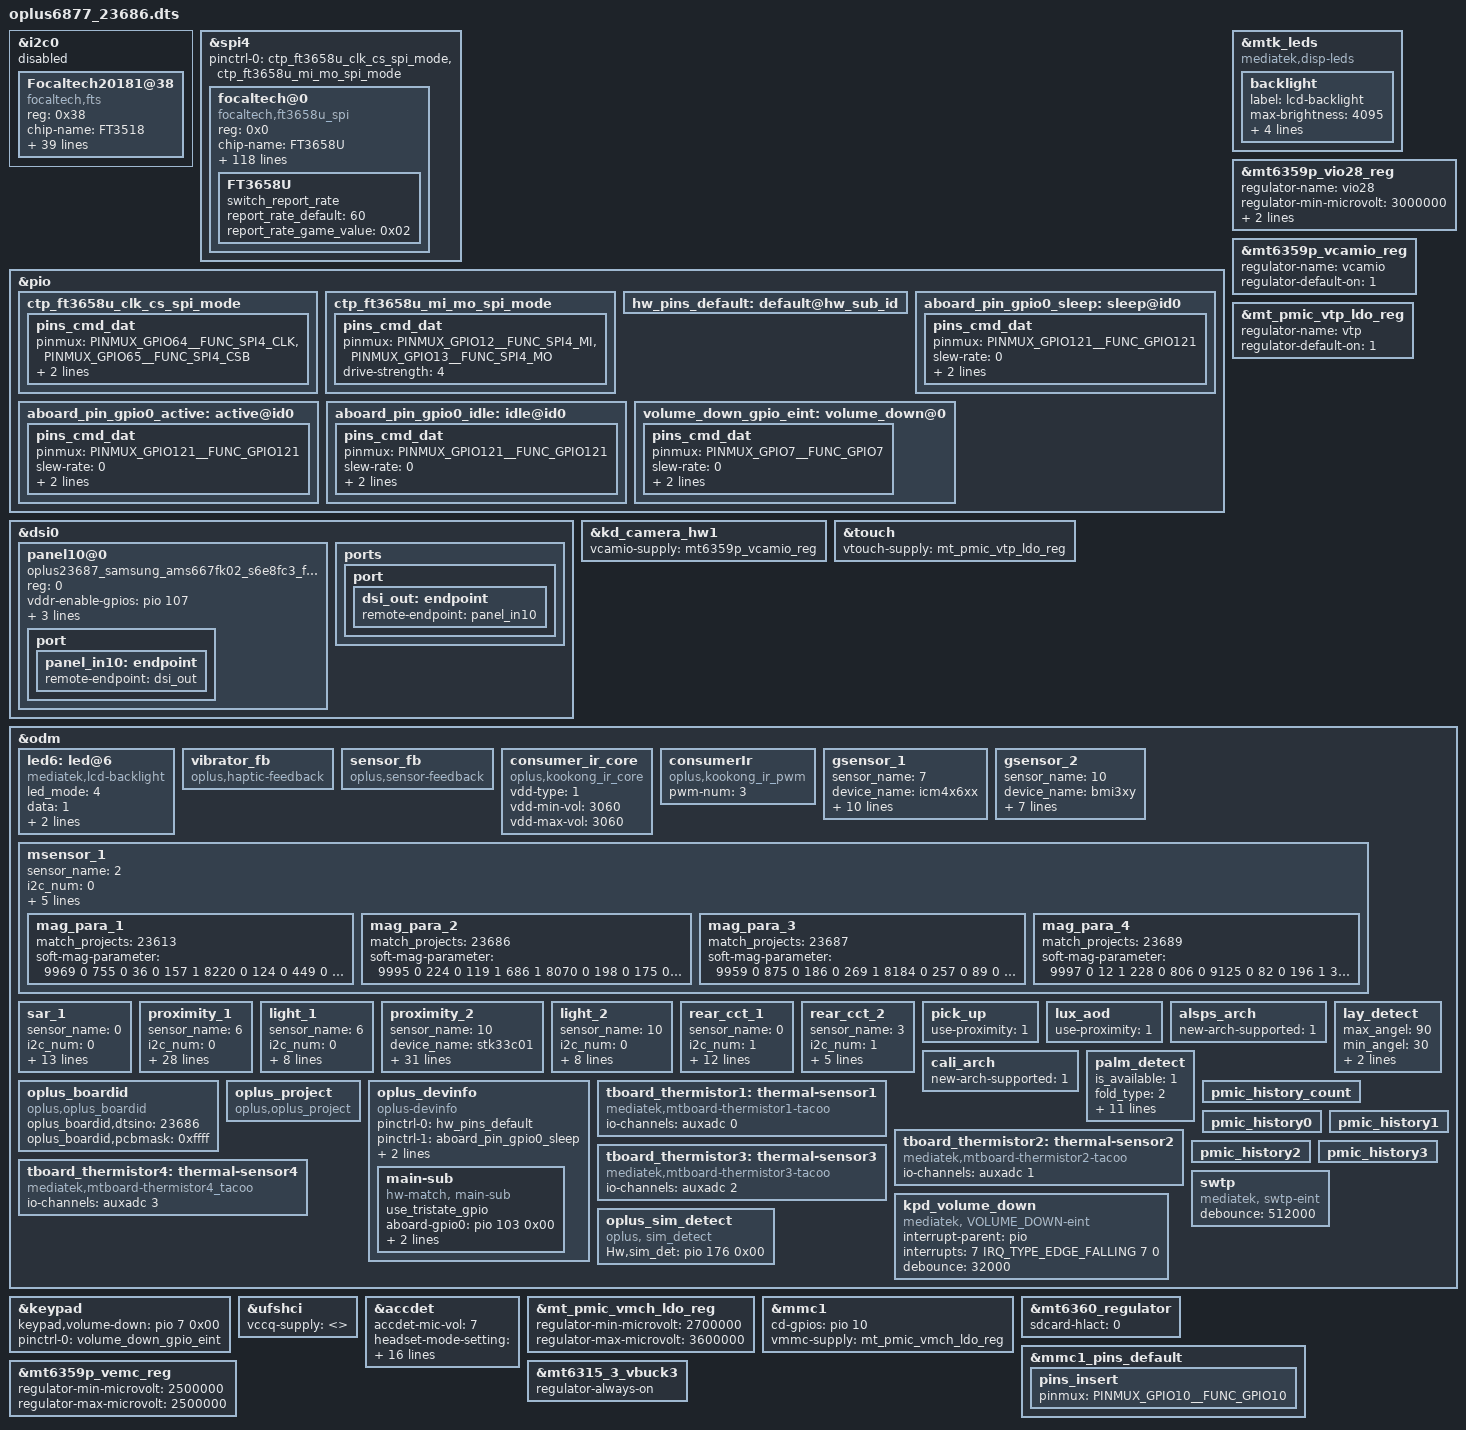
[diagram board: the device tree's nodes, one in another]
// SPDX-License-Identifier: (GPL-2.0 OR MIT)
/*
 * Copyright (C) 2022 MediaTek Inc.
 */
#include "k6877v1_64.dts"

/* #ifdef CONFIG_UFF_FINGERPRINT */
#include "mediatek/oplus_uff_23613_23686_23687.dtsi"
/* #endif CONFIG_UFF_FINGERPRINT */

/*touch start*/

&i2c0 {
	status = "disable";
		Focaltech20181@38 {
		compatible = "focaltech,fts";
		reg = <0x38>;
		chip-name = "FT3518";

		/* Interrupt && Irq-gpio */
		interrupt-parent = <&pio>;
		interrupts = <14 0x2002>;

		/* Power Config */
		vdd_2v8-supply  = <&mt_pmic_vtp_ldo_reg>;
		vdd_2v8_volt = <3000000>;

		/* Other HW Resource */
		irq-gpio = <&pio 14 0x2002>;
		reset-gpio = <&pio 15 0x1>;
		//pinctrl-names = "default";
		//pinctrl-0 = <&ctp_ts_int_active &ctp_ts_reset_active>;

		vid_len = <2>;
		tp_type = <8>;
		// type of tp_dev ,TP-SAMSUNG = 8;
		platform_support_project = <23231>;
		platform_support_project_dir = <23231>;
		platform_support_project_commandline = "default_commandline", "default_commandline", "default_commandline";

		touchpanel,max-num-support = <10>;
		touchpanel,tx-rx-num = <16 34>;
		touchpanel,panel-coords = <4320 9600>;
		touchpanel,display-coords = <1080 2400>;
		touchpanel,touchmajor-limit = <0 216>;
		touchpanel,report-rate = <120 180>;
		touchpanel,smooth-level = <255 2 15 25 45 60>;
		touchpanel,smooth-level-charging = <255 15 20 25 45 60>;
		touchpanel,sensitive-level = <255 20 16 13 10 5>;
		touchpanel,single-optimized-time = <8>;

		//prevention,dead_area_width = <20 20>;
		//prevention,condition_area_width = <60 60 160 160>;
		//prevention,eli_area_width = <240 1000 1200 240>;

		/* SW Support Feature Control */
		black_gesture_support;
		//black_gesture_indep_support;
		fw_edge_limit_support;
		pressure_report_support;
		charger_pump_support;
		game_switch_support;
		smart_gesture_support;
		fw_update_app_support;
		fingerprint_underscreen_support;
		headset_pump_support;
		//irq_need_dev_resume_ok;
		health_monitor_v2_support;
		high_resolution_support;
		//esd_handle_support;
		lcd_tp_refresh_support;
		exception_upload_support;
		/*
		 *Virtual Key Config:
		 *1:touchpanel,button-type: <virtualkey_type  supportted_button-map>
		 *virtualkey_type:
		 *Type 1: using board_properties
		 *Type 2: using same IC (button zone&& touch zone are seprate)
		 *Type 3: using diffrent IC (button zone&& touch zone are seprate)
		 *Type 4: No need of virtual key process
		 *supportted_button-map:select|menu|home|back
		 *
		 *2:touchpanel,button-map
		 *type (X1,Y1)(X2,Y2)(X3,Y3)(Width_X,Hight_Y)--Only when button-type is 0
		 */
		touchpanel,button-type = <4>;
		touchpanel.button-TRx = <0 0>;
	};
};

&spi4 {
	status = "okay";
	#address-cells = <1>;
	#size-cells = <0>;

	pinctrl-names = "default";
	pinctrl-0 = <&ctp_ft3658u_clk_cs_spi_mode>, <&ctp_ft3658u_mi_mo_spi_mode>;

	focaltech@0{
		compatible = "focaltech,ft3658u_spi";
		reg = <0x0>;
		chip-name = "FT3658U";
		status = "okay";
		spi-max-frequency = <6000000>;
		/* Interrupt && Irq-gpio */
		interrupt-parent = <&pio>;
		interrupts = <14 0x2002>;
		panel_type = <8>; /* panel-SAMSUNG*/
		/* Power Config */
		project_id = <23687>;
		vdd_2v8-supply  = <&mt_pmic_vtp_ldo_reg>;
		vdd_2v8_volt = <3000000>;



		/* Other HW Resource */

		irq-gpio = <&pio 14 0x2002>;
		reset-gpio = <&pio 15 0x1>;

		touchpanel,max-num-support = <10>;
		touchpanel,tx-rx-num = <16 34>;
		earsense,tx-rx-num = <17 18>;
		touchpanel,panel-coords = <8640 19200>;
		touchpanel,display-coords = <1080 2400>;
		touchpanel,touchmajor-limit = <128 216>;
		touchpanel,elimination-range = <20 200 200>;
		//touchpanel,int-mode = <1>; /*0: interrupt and disable, 1:interrupt and not disable*/
		touchpanel,msecs-to-jiffies-time = <150>;
		touchpanel,smooth-level = <0 110 115 120 140 155>;
		touchpanel,smooth-level-charging = <0 110 115 120 140 155>;
		touchpanel,sensitive-level = <0 19 16 14 13 10>;
		touchpanel,tp-index = <0>;
		touchpanel,high-frame-rate-time = <20>;

		vid_len = <2>;
		firmware_name = "0xAB30500";
		tp_type = <8>; /* panel-SAMSUNG*/
		platform_support_project = <23613 23686 23687 23689 23707 23709>;
		platform_support_project_dir = <23687 23687 23687 23687 23687 23687>;
		platform_support_project_commandline = "default_commandline","default_commandline","default_commandline","default_commandline","default_commandline","default_commandline";

        prevention,curved_screen_V2;
        prevention,grip_disable_level = <6>;
        prevention,updelay_time_ms = <30>;
        prevention,makeup_cnt_weight = <4 1 2 2 2>;
        prevention,large_corner_range = <960 2400>;
        prevention,large_corner_judge_condition = <500 300 800 7 7>;
        prevention,trx_reject_condition = <9 6 7>;
        prevention,trx_strict_reject_condition = <8 5 6>;
        prevention,large_judge_time_ms = <500 50 30>;
        prevention,large_exit_condition = <8 8 2>;
        prevention,single_channel_width = <160 160>;
        prevention,normal_tap_condition = <10 350>;
        prevention,long_edge_condition = <200 80 180 80>;
        prevention,long_strict_edge_condition = <160 60>;
        prevention,long_fingerhold_condition = <50 6 4 4>;
        prevention,short_edge_condition = <200 80 180 80>;
        prevention,short_strict_edge_condition = <160 60>;
        prevention,large_strict_exit_condition = <4 4>;
        prevention,top_corner_config = <440 1200 360>;
        prevention,edge_swipe_config = <240 960>;

        prevention,curved_screen_V4;
        prevention,long_eliminate_point_type = <2 8640 6400 240 19200 300 1>;
        prevention,long_fingerhold_condition2 = <420 0 0 0>;
        prevention,top_corner_config2 = <3 80 480 0 0>;
        prevention,hor_long_top_corner_config = <240 1600 0 0>;
        prevention,top_middle_config = <8640 800 800 0>;
        prevention,corner_eliminate_point_type = <0 960 1600 1>;
        prevention,finger_hold_differ_size = <1 0 240 300>;
        prevention,finger_hold_max_rx_exit_distance = <5 240 1600>;
        prevention,max_rx_exit_distance = <1 5 150 240 1600>;
        prevention,dynamic_finger_hold_exit_distance = <1 240 1600 360>;
        prevention,edge_sliding_matched_support = <1 150 3 0>;

        //grip v4.2 reclining mode
        prevention,reclining_mode_support = <1>;
        prevention,long_eliminate_point_type_recli = <2 8640 6400 240 19200 500 0>;
        prevention,finger_hold_differ_size_recli = <1 0 240 400>;
        prevention,finger_hold_max_rx_exit_distance_recli = <4 240 1600>;
        prevention,max_rx_exit_distance_recli = <1 4 100 240 1600>;
        prevention,dynamic_finger_hold_exit_distance_recli = <1 240 1600 360>;
        prevention,edge_sliding_matched_support_recli = <1 200 3 0>;
        prevention,long_edge_condition_recli = <160 80 120 80>;

		/* SW Support Feature Control */
		//esd_handle_support;
		//register-is-16bit;
		//wireless_charger_support;
		headset_pump_support;
		//fw_edge_limit_support;

		health_monitor_support;
		black_gesture_support;
		charger_pump_support;
		//lcd_tp_refresh_support;
		fw_update_app_support;
		smart_gesture_support;
		game_switch_support;
		report_flow_unlock_support;
		kernel_grip_support;
		fingerprint_underscreen_support;
		pressure_report_support;
		touchpanel,single-optimized-time = <8>;
		auto_test_force_pass_support;
		snr_read_support;
		high_resolution_support_x8;
		algorithm_support;
		screenoff_fingerprint_info_support;
		irq_need_dev_resume_ok;
		sportify_aod_gesture_support;
		black_gesture_indep_support;
		thermal_detect_support;
		exception_upload_support;
		palm_to_sleep_support;
		diaphragm_touch_support;
		force_water_mode_support;

		/*
		 *Virtual Key Config:
		 *1:touchpanel,button-type: <virtualkey_type  supportted_button-map>
		 *virtualkey_type:
		 *Type 1: using board_properties
		 *Type 2: using same IC (button zone&& touch zone are seprate)
		 *Type 3: using diffrent IC (button zone&& touch zone are seprate)
		 *Type 4: No need of virtual key process
		 *supportted_button-map:select|menu|home|back
		 *
		 *2:touchpanel,button-map
		 *type (X1,Y1)(X2,Y2)(X3,Y3)(Width_X,Hight_Y)--Only when button-type is 0
		 */
		touchpanel,button-type = <4>;
		touchpanel.button-TRx = <0 0>;

		FT3658U {
			switch_report_rate;
			report_rate_default = <60>;
			report_rate_game_value = <0x02>;
		};
	};
};

&pio {
	ctp_ft3658u_clk_cs_spi_mode: ctp_ft3658u_clk_cs_spi_mode{
		pins_cmd_dat {
			pinmux = <PINMUX_GPIO64__FUNC_SPI4_CLK>,
				<PINMUX_GPIO65__FUNC_SPI4_CSB>;
			mediatek,drive-strength-adv = <0>;/*EH[2:0]*/
			drive-strength = <4>;
		};
	};
	ctp_ft3658u_mi_mo_spi_mode: ctp_ft3658u_mi_mo_spi_mode {
		pins_cmd_dat {
			pinmux = <PINMUX_GPIO12__FUNC_SPI4_MI>,
				<PINMUX_GPIO13__FUNC_SPI4_MO>;
			drive-strength = <4>;
		};
	};

};
/*touch end*/



&dsi0 {
	status = "okay";
	#address-cells = <1>;
	#size-cells = <0>;
	panel10@0 {
		compatible = "oplus23687_samsung_ams667fk02_s6e8fc3_fhdp_dsi_vdo";
		reg = <0>;
		vddr-enable-gpios = <&pio 107 0>;
		vci-enable-gpios = <&pio 105 0>;
		reset-gpios = <&pio 40 0>;
                oplus,ofp-fp-type = <0x200>;
		pinctrl-names = "default";
		port {
			panel_in10: endpoint {
				remote-endpoint = <&dsi_out>;
			};
		};
	};
	ports {
		port {
			dsi_out: endpoint {
				remote-endpoint = <&panel_in10>;
			};
		};
	};
};

&mtk_leds {
	compatible = "mediatek,disp-leds";
	backlight {
		label = "lcd-backlight";
		max-brightness = <4095>;
		max-hw-brightness = <4095>;
		led-bits = <12>;
		trans-bits = <12>;
		default-state = "on";
	};
};

&mt6359p_vio28_reg {
	regulator-name = "vio28";
	regulator-min-microvolt = <3000000>;
	regulator-max-microvolt = <3000000>;
	regulator-enable-ramp-delay = <0>;
};

&mt6359p_vcamio_reg {
	regulator-name = "vcamio";
	regulator-default-on = <1>; /* 0:skip, 1: off, 2:on */
	status = "okay";
};
&mt_pmic_vtp_ldo_reg {
	regulator-name = "vtp";
	regulator-default-on = <1>; /* 0:skip, 1: off, 2:on */
	status = "okay";
};

&kd_camera_hw1 {
	vcamio-supply = <&mt6359p_vcamio_reg>;
	status = "okay";
};

&touch {
	vtouch-supply = <&mt_pmic_vtp_ldo_reg>;
	status = "okay";
};

&odm {
/*
	/delete-node/ led@6;
*/

	led6:led@6 {
		compatible = "mediatek,lcd-backlight";
		led_mode = <4>;
		data = <1>;
		led_config = <8 11>;
		pwm_config = <0 1 0 0 0>;
	};

	vibrator_fb:vibrator_fb {
		compatible = "oplus,haptic-feedback";
	};
/* sensor start */
	sensor_fb: sensor_fb {
		compatible = "oplus,sensor-feedback";
	};
	consumer_ir_core: consumer_ir_core {
		compatible = "oplus,kookong_ir_core";
		status = "okay";
		vdd-type = <1>;
		vdd-min-vol = <3060>;
		vdd-max-vol = <3060>;
	};
	consumerIr: consumerIr {
		compatible = "oplus,kookong_ir_pwm";
		status = "okay";
		pwm-num = <3>;
	};
	/*
	enum {
		LIS3DH,
		LSM6DS3,
		BMI160,
		LIS2HH12,
		LSM6DSM,
		BMI2XY,
		LSM6DSO,
		BMA4XY,
		SC7A20,
		ICM4X6XX,
	};
	*/
	gsensor_1: gsensor_1 {
		status = "okay";
		sensor_name = <7>;//ICM4X6XX
		device_name = "icm4x6xx";
		i2c_num = <2>;
		i2c_addr = <0>;
		direction = <2>;
		eint_num = <1>;
		step_count_7_en = <1>;
		config_miso = <1>;
		correct_y_bias = <1>;
		gyro_cali_version= <2>;
		gyro_cali_range = <350>; //0.35 rad/s
		acc_cali_range= <300 300 300>; //250mg
	};
	gsensor_2: gsensor_2 {
		status = "okay";
		sensor_name = <10>;//BMI3XY
		device_name = "bmi3xy";
		i2c_num = <2>;
		i2c_addr = <0>;
		direction = <1>;
		eint_num = <1>;
		gyro_cali_version= <2>;
		gyro_cali_range = <350>; //0.35 rad/s
		acc_cali_range= <300 300 300>; //250mg
	};
	/*
	enum {
		AKM09911,
		MMC3530,
		MMC5603,
		MXG4300,
	};
	*/
	msensor_1: msensor_1 {
		status = "okay";
		sensor_name = <2>;//MMC5603
		i2c_num = <0>;
		i2c_addr = <48>;
		direction = <3>;
		eint_num = <0>;
		para_num = <4>;
		libname = "mmc";
		mag_para_1 {
			match_projects = <23613>;
			soft-mag-parameter = <9969 0 755 0 36 0 157 1 8220 0 124 0 449 0 24 0 10391 0>;
		};
		mag_para_2 {
			match_projects = <23686>;
			soft-mag-parameter = <9995 0 224 0 119 1 686 1 8070 0 198 0 175 0 387 0 10181 0>;
		};
		mag_para_3 {
			match_projects = <23687>;
			soft-mag-parameter = <9959 0 875 0 186 0 269 1 8184 0 257 0 89 0 120 0 10452 0>;
		};
		mag_para_4 {
			match_projects = <23689>;
			soft-mag-parameter = <9997 0 12 1 228 0 806 0 9125 0 82 0 196 1 333 0 10375 0>;
		};
	};
	sar_1: sar_1 {
		status = "okay";
		sensor_name = <0>;//SX933x
		i2c_num = <0>;
		i2c_addr = <40>;
		direction = <4>;
		eint_num = <13>;
		channel_num = <2>;
		channel_0_min = <0>;
		channel_0_max = <70000>;
		channel_1_min = <0>;
		channel_1_max = <70000>;
		channel_2_min = <0>;
		channel_2_max = <70000>;
		channel_3_min = <0>;
		channel_3_max = <70000>;
		reg_table_num = <3>;
	};
	/*
	enum {
		TMD2725,
		APSD9922,
		STK3335,
		STK3331,
		STK2232,
		TCS3701,
		STK32600,
	};
	*/
	proximity_1: proximity_1 {
		status = "okay";
		sensor_name = <6>;//STK32600
		i2c_num = <0>;
		i2c_addr = <72>;
		direction = <4>;
		eint_num = <2>;
		low_step = <300>;
		high_step = <400>;
		low_limit = <400>;
		high_limit = <600>;
		dirty_low_step = <300>;
		dirty_high_step = <400>;
		ps_dirty_limit = <1800>;
		ps_ir_limit = <2000>;
		ps_adjust_min = <0>;
		ps_adjust_max = <1850>;
		sampling_count = <5>;
		step_max = <400>;
		step_min = <100>;
		step_div = <2000>;
		anti_shake_delta = <70>;
		dynamic_cali_max = <5000>;
		raw2offset_radio = <1000>;
		offset_max = <60000>;
		offset_range_min = <0>;
		offset_range_max = <65535>;
		force_cali_limit = <2000>;
		cali_jitter_limit = <30>;
		cal_offset_margin = <3000>;
		sensor-reg = <0x03 0x28>;
		is_use_force_cali = <1>;
	};
	light_1: light_1 {
		status = "okay";
		sensor_name = <6>;//STK32600
		i2c_num = <0>;
		i2c_addr = <72>;
		direction = <4>;
		eint_num = <2>;
		als_buffer_length =<8>;
		als_ratio = <110>;
		als_type = <2>;//<1-normal;2-under screen;3-normal needed compensation>
		device_name = "stk32600";
		use_als_c2 = <1>;
	};
	proximity_2: proximity_2 {
		status = "okay";
		sensor_name = <10>;//STK33C01
		device_name = "stk33c01";
		i2c_num = <0>;
		i2c_addr = <72>;
		direction = <4>;
		eint_num = <2>;
		low_step = <300>;
		high_step = <400>;
		low_limit = <400>;
		high_limit = <600>;
		dirty_low_step = <300>;
		dirty_high_step = <400>;
		ps_dirty_limit = <1800>;
		ps_ir_limit = <2000>;
		ps_adjust_min = <0>;
		ps_adjust_max = <1850>;
		sampling_count = <5>;
		step_max = <400>;
		step_min = <100>;
		step_div = <2000>;
		anti_shake_delta = <70>;
		dynamic_cali_max = <5000>;
		raw2offset_radio = <1000>;
		offset_max = <60000>;
		offset_range_min = <0>;
		offset_range_max = <65534>;
		force_cali_limit = <2000>;
		cali_jitter_limit = <30>;
		cal_offset_margin = <3000>;
		is_use_force_cali = <1>;
		parameter-number = <8>;
		sensor-reg = <0x01 0x44
				0x03 0x28
				0x05 0x3F
				0xDB 0x00>; //override special reg
	};
	light_2: light_2 {
		status = "okay";
		sensor_name = <10>;//STK33C01
		i2c_num = <0>;
		i2c_addr = <72>;
		direction = <4>;
		eint_num = <2>;
		als_buffer_length =<8>;
		als_ratio = <110>;
		als_coef_ratio = <88>;
		als_type = <2>;//<1-normal;2-under screen;3-normal needed compensation>
		device_name = "stk33c01";

	};
	/*
	enum {
		STK37600,
		MN29005,
		TCS3408,
	};
	*/
	rear_cct_1: rear_cct_1 {
		status = "okay";
		sensor_name = <0>;//STK37600
		i2c_num = <1>;
		i2c_addr = <0x48>;
		direction = <0>;
		eint_num = <10>;
		available_sensor = <7>; // bit 0: rear als, bit 1: rear cct, bit 2: rear flicker
		gold_rear_cct_3k = <11083 14060 1700 488 64 42136>; // 3000k gold parameter
		gold_rear_cct_6k = <8488 13068 3928 372 64 42964>;  // 3000k gold parameter
		device_name = "stk37600";
		cct_coef_Lir = <9116000 0 259000 0 1711000 1 7351000 0 12875000 0
				1686000 0 3545000 0 6606000 0 51505000 0 3221000 1
				2492000 1 2826000 1>;
		cct_coef_Hir = <178000 1 14775000 1 36798000 1 13552000 0 24758000 0
				31340000 0 3274000 1 7368000 1 19817000 0 161000 1
				23000 0 392000 0>;
	};
	rear_cct_2: rear_cct_2 {
		status = "okay";
		sensor_name = <3>;//SIP1221LR1N
		i2c_num = <1>;
		i2c_addr = <0x59>;
		direction = <0>;
		eint_num = <10>;
		available_sensor = <4>; // bit 0: rear als, bit 1: rear cct, bit 2: rear flicker
		device_name = "sip1221lr1n";
	};
	pick_up: pick_up {
		status = "okay";
		use-proximity = <1>;
	};
	lux_aod: lux_aod {
		status = "okay";
		use-proximity = <1>;
	};
	alsps_arch: alsps_arch {
		status = "okay";
		new-arch-supported = <1>;
	};
	cali_arch: cali_arch {
		status = "okay";
		new-arch-supported = <1>;
	};
	lay_detect: lay_detect{
		status = "okay";
		max_angel = <90>;
		min_angel = <30>;
		lay_in_time = <10>;
		lay_out_time = <3>;
	};
	palm_detect: palm_detect{
		status = "okay";
		is_available = <1>;
		fold_type = <2>;
		prox_type = <0>;
		x_limit = <1>;
		y_limit = <6>;
		z_limit = <6>;
		delta_ms_limit = <5000>;
		delta_ms_low = <200>;
		x_gyro_limit = <300000>;
		y_gyro_limit = <300000>;
		z_gyro_limit = <300000>;
		move_limit = <8>;
		als_limit = <3>;
	};
/* sensor end */

	oplus_boardid:oplus_boardid {
		compatible = "oplus,oplus_boardid";
		oplus_boardid,dtsino="23686";//only one u32
		oplus_boardid,pcbmask="0xffff";//all mask 0xffff
	};

/* OPLUS_BUG_STABILITY oplus project start */
	oplus_project:oplus_project {
		compatible = "oplus,oplus_project";
	};
	oplus_devinfo:oplus_devinfo {
		compatible = "oplus-devinfo";

		pinctrl-names = "default", "aboard_gpio0_sleep", "aboard_gpio0_active", "aboard_gpio0_idle";
		pinctrl-0 = <&hw_pins_default>;
		pinctrl-1 = <&aboard_pin_gpio0_sleep>;
		pinctrl-2 = <&aboard_pin_gpio0_active>;
		pinctrl-3 = <&aboard_pin_gpio0_idle>;
		main-sub {
			use_tristate_gpio;
			compatible = "hw-match, main-sub";
			aboard-gpio0 = <&pio 103 0x00>;
			aboard-patterns = <2 1 0>;
			/*main board*/
			match-projects = <23613 23686 23687>;
		};
	};

/* OPLUS_BUG_STABILITY oplus project end */

/* 20221216, add for AP, 4G pA, 5G PA, charger, sub_bat, flashlight ntc*/
 	tboard_thermistor1: thermal-sensor1 {
 		compatible = "mediatek,mtboard-thermistor1-tacoo";
 		io-channels = <&auxadc 0>;
 		io-channel-names = "thermistor-ch0";
 	};
 	tboard_thermistor2: thermal-sensor2 {
 		compatible = "mediatek,mtboard-thermistor2-tacoo";
 		io-channels = <&auxadc 1>;
 		io-channel-names = "thermistor-ch1";
 	};
 	tboard_thermistor3: thermal-sensor3 {
 		compatible = "mediatek,mtboard-thermistor3-tacoo";
 		io-channels = <&auxadc 2>;
 		io-channel-names = "thermistor-ch2";
 	};
	tboard_thermistor4: thermal-sensor4 {
 		compatible = "mediatek,mtboard-thermistor4_tacoo";
 		io-channels = <&auxadc 3>;
 		io-channel-names = "thermistor-ch3";
	};
	kpd_volume_down:kpd_volume_down {
		compatible = "mediatek, VOLUME_DOWN-eint";
		interrupt-parent = <&pio>;
		interrupts = <7 IRQ_TYPE_EDGE_FALLING 7 0>;/*TRQ num 29 is linked with gpio29 (mt6877)*/
		debounce = <32000>;
		status = "okay";
	};

	pmic_history_count:pmic_history_count {
	};
	pmic_history0:pmic_history0 {
	};
	pmic_history1:pmic_history1 {
	};
	pmic_history2:pmic_history2 {
	};
	pmic_history3:pmic_history3 {
	};
	//#ifdef OPLUS_VENDOR_SWTP
	swtp: swtp {
		compatible = "mediatek, swtp-eint";
		debounce = <512000>;
	};
	//#endif  /*OPLUS_VENDOR_SWTP*/

};

&odm {
/* Add for sim detect */
    oplus_sim_detect {
        compatible = "oplus, sim_detect";
        Hw,sim_det = <&pio 176 0x00>;
    };
};

&pio {
        hw_pins_default:default@hw_sub_id {
        };

        aboard_pin_gpio0_sleep:sleep@id0 {
                pins_cmd_dat {
                        pinmux = <PINMUX_GPIO121__FUNC_GPIO121>;
                        slew-rate = <0>;
                        bias-pull-down;
                        input-enable;
                };
        };

        aboard_pin_gpio0_active:active@id0 {
                pins_cmd_dat {
                        pinmux = <PINMUX_GPIO121__FUNC_GPIO121>;
                        slew-rate = <0>;
                        bias-pull-up;
                        input-enable;
                };
        };

        aboard_pin_gpio0_idle:idle@id0 {
                pins_cmd_dat {
                        pinmux = <PINMUX_GPIO121__FUNC_GPIO121>;
                        slew-rate = <0>;
                        bias-disable;
                        input-enable;
                };
        };
};

&keypad {
        keypad,volume-down = <&pio 7 0x00>;
        pinctrl-names = "volume_down_as_int";
        pinctrl-0 = <&volume_down_gpio_eint>;
        status = "okay";
};

&pio {
        volume_down_gpio_eint:volume_down@0{
                pins_cmd_dat {
                        pinmux = <PINMUX_GPIO7__FUNC_GPIO7>;
                        slew-rate = <0>;  /*direction 0:in, 1:out*/
                        input-enable;
			bias-disable;
                };
        };
};

&ufshci {
    vccq-supply = <>;
};

&accdet {
	/* accdet micbias voltage: 0x09:2.85v 0x08:2.8v 0x07,
	 * 2.7v;0x05,2.5v;0x02,1.9v
	 */
	accdet-mic-vol = <7>;
	/* accdet pwm_width, pwm_thresh, fall_delay, rise_delay
	 * debounce0, debounce1, debounce3, debounce4
	 * eint pwm_width, eint pwm_thresh
	 * eint deb(debounce0, debounce1, debounce2, debounce3), inv_debounce
	 */
	//#ifdef OPLUS_ARCH_EXTENDS
	/* Modify for bug 136344 */
	headset-mode-setting = <0x500 0x500 1 0x1f0
				0x1325 0x800 0x3D4 0x44
				0x0 0x7
				0x5 0x9 0x9 0xd 0xe>;
	//#else /* OPLUS_ARCH_EXTENDS */
	/*headset-mode-setting = <0x500 0x500 1 0x1f0
	*                      0x800 0x800 0x20 0x44
	*                      0x4 0x1
	*                      0x5 0x3 0x3 0x5 0xe>;
	*/
	//#endif /* OPLUS_ARCH_EXTENDS */
	accdet-plugout-debounce = <1>;
	/*1:ACC mode, 2:low cost without in bias, 6:low cost with in bias*/
	accdet-mic-mode = <2>;
	/*0--MD_MAX--UP_MAX--DW_MAX*/
	headset-three-key-threshold = <0 82 170 306>;
	//#else
	//headset-three-key-threshold = <0 80 220 400>;
	//#endif
	headset-three-key-threshold-CDD = <0 121 192 600>;
	/*0--MD_MAX--VOICE_MAX--UP_MAX--DW_MAX*/
	headset-four-key-threshold = <0 58 121 192 400>;

//#ifdef OPLUS_ARCH_EXTENDS
	/* moisture HW mode config start. Enable moisture detection or not
	 * default use HW mode for moisture detection
	 */
	moisture_detect_enable = <1>;
//#endif /* OPLUS_ARCH_EXTENDS */
	/* select VTH to 2v and 500k, use internal resitance */
	eint_use_ext_res = <0>;
//#ifdef OPLUS_ARCH_EXTENDS
	/* enable eint detection mode, if moisture detection enable
	 * eint_detect_mode = moisture_detect_mode;otherwise, select
	 * eint_detect_mode = 4 as DEFAULT
	 */
	eint_detect_mode = <5>;
	/* enable moisture detection mode, if moisture detection enable
	 * eint_detect_mode = moisture_detect_mode
	 */
	moisture_detect_mode = <5>;
	/* select 0: 2.8V; 1: 2.4V; 2: 2V; 3: VTH=MVTH(VTH2) */
	moisture_comp_vth = <2>;
	/* vref2 voltage for different water impedance */
//#ifdef OPLUS_ARCH_EXTENDS
	moisture_comp_vref2 = <2>;
//
	/* vref2 voltage for different water impedance */
//	moisture_comp_vref2 = <0>;
//#endif
	/* moisture HW mode config end */

	/* moisture SW mode config start, use external resister or not.
	 * DEFAULT NOT NEED
	 */
	moisture_use_ext_res = <0>;
	/* moisture external resister ohm, SW mode by auxadc */
	moisture-external-r = <2000000>;
	/* moisture internal resister ohm, SW mode by auxadc */
	moisture-internal-r = <47000>;
	/* moisture of water resister ohm, SW mode by auxadc*/
	moisture-water-r = <10000>;
	/* moisture SW mode config end */
//#endif /* OPLUS_ARCH_EXTENDS */
	status = "okay";
};

&mt_pmic_vmch_ldo_reg {
    regulator-min-microvolt = <2700000>;
    regulator-max-microvolt = <3600000>;
};

&mmc1 {
    cd-gpios = <&pio 10 0>;
    status = "okay";
    vmmc-supply = <&mt_pmic_vmch_ldo_reg>;
};

&mt6360_regulator {
    sdcard-hlact = <0>;
};

&mmc1_pins_default {
	pins_insert {
		pinmux = <PINMUX_GPIO10__FUNC_GPIO10>;
	};
};

&mt6359p_vemc_reg {
	regulator-min-microvolt = <2500000>;
	regulator-max-microvolt = <2500000>;
};

&mt6315_3_vbuck3 {
	regulator-always-on;
};

#include "oplus6877_23686/cust.dtsi"
//#include "mediatek/nfc/mt6877_burberry_pn560.dtsi"
//#include "mediatek/oplus_chg/cust_mt6877_oplus_charge_23231.dtsi"
#include "mediatek/cust_mt6877_camera_23687.dtsi"
#include "mediatek/cust_mt6877_23686_charge.dtsi"
//#include "mediatek/cust_mt6877_camera.dtsi"
#include "mediatek/mt6878-sia81x9.dtsi"
/*End of this file, DO NOT ADD ANYTHING HERE*/

